# STM32G030 register map
File version: 1.6
CPU: CM0 r0p1, little endian, MPU, no FPU, 2 interrupt priority bits
Registers are 32-bit, read-write, reset 0x0 unless marked. A register's access mark holds for its fields unless they carry their own. Offsets are from the block's base; [hi:lo] are bit positions; {n}, {i} and the like mark numbered series.

## FLASH
Base 0x40022000
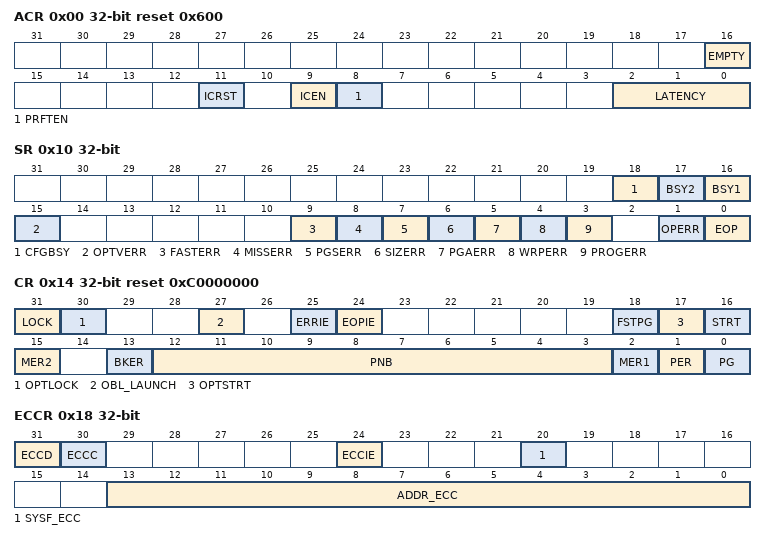
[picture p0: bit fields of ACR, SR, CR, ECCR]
0x00 ACR reset 0x600 — Access control register
  [16] EMPTY — Flash User area empty
  [11] ICRST — Instruction cache reset
  [9] ICEN — Instruction cache enable
  [8] PRFTEN — Prefetch enable
  [2:0] LATENCY
0x08 KEYR wo — Flash key register
  [31:0] KEY — KEYR
0x0C OPTKEYR wo — Option byte key register
  [31:0] OPTKEY — Option byte key
0x10 SR — Status register
  [18] CFGBSY — Programming or erase configuration busy.
  [17] BSY2
  [16] BSY1
  [15] OPTVERR — Option and Engineering bits loading validity error
  [9] FASTERR — Fast programming error
  [8] MISSERR — Fast programming data miss error
  [7] PGSERR — Programming sequence error
  [6] SIZERR — Size error
  [5] PGAERR — Programming alignment error
  [4] WRPERR — Write protected error
  [3] PROGERR — Programming error
  [1] OPERR — Operation error
  [0] EOP — End of operation
0x14 CR reset 0xC0000000 — Flash control register
  [31] LOCK — FLASH_CR Lock
  [30] OPTLOCK — Options Lock
  [27] OBL_LAUNCH — Force the option byte loading
  [25] ERRIE — Error interrupt enable
  [24] EOPIE — End of operation interrupt enable
  [18] FSTPG — Fast programming
  [17] OPTSTRT — Options modification start
  [16] STRT — Start
  [15] MER2
  [13] BKER
  [12:3] PNB — Page number
  [2] MER1 — Mass erase
  [1] PER — Page erase
  [0] PG — Programming
0x18 ECCR access per field — Flash ECC register
  [31] ECCD rw — ECC detection
  [30] ECCC rw — ECC correction
  [24] ECCIE rw — ECC correction interrupt enable
  [20] SYSF_ECC ro — ECC fail for Corrected ECC Error or Double ECC Error in info block
  [13:0] ADDR_ECC ro — ECC fail address
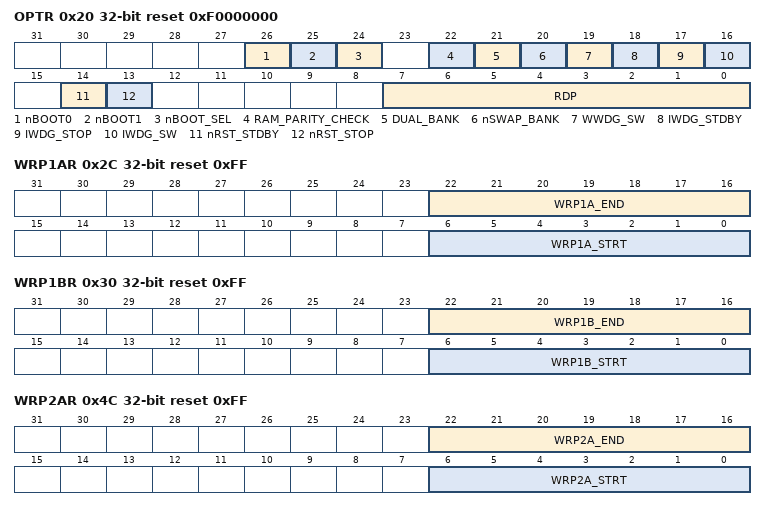
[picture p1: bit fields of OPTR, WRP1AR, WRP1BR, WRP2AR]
0x20 OPTR reset 0xF0000000 — Flash option register
  [26] nBOOT0 — nBOOT0 option bit
  [25] nBOOT1 — Boot configuration
  [24] nBOOT_SEL
  [22] RAM_PARITY_CHECK — SRAM parity check control
  [21] DUAL_BANK
  [20] nSWAP_BANK
  [19] WWDG_SW — Window watchdog selection
  [18] IWDG_STDBY — Independent watchdog counter freeze in Standby mode
  [17] IWDG_STOP — Independent watchdog counter freeze in Stop mode
  [16] IWDG_SW — Independent watchdog selection
  [14] nRST_STDBY
  [13] nRST_STOP
  [7:0] RDP — Read protection level
0x2C WRP1AR reset 0xFF — Flash WRP area A address register
  [22:16] WRP1A_END — WRP area A end offset
  [6:0] WRP1A_STRT — WRP area A start offset
0x30 WRP1BR reset 0xFF — Flash WRP area B address register
  [22:16] WRP1B_END — WRP area B end offset
  [6:0] WRP1B_STRT — WRP area B start offset
0x4C WRP2AR reset 0xFF — FLASH WRP2 area A address register
  [22:16] WRP2A_END, [6:0] WRP2A_STRT
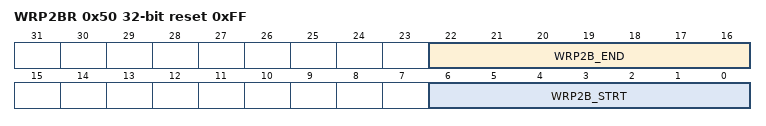
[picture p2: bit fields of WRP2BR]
0x50 WRP2BR reset 0xFF — FLASH WRP2 area B address register
  [22:16] WRP2B_END, [6:0] WRP2B_STRT

## PWR — Power control
Base 0x40007000
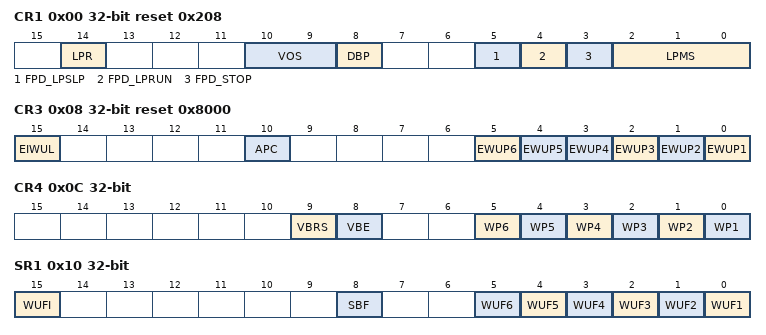
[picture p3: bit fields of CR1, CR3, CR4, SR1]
0x00 CR1 reset 0x208 — Power control register 1
  [14] LPR — Low-power run
  [10:9] VOS — Voltage scaling range selection
  [8] DBP — Disable backup domain write protection
  [5] FPD_LPSLP — Flash memory powered down during Low-power sleep mode
  [4] FPD_LPRUN — Flash memory powered down during Low-power run mode
  [3] FPD_STOP — Flash memory powered down during Stop mode
  [2:0] LPMS — Low-power mode selection
0x04 CR2 — Power control register 2
  [10] USV
0x08 CR3 reset 0x8000 — Power control register 3
  [15] EIWUL — Enable internal wakeup line
  [10] APC — Apply pull-up and pull-down configuration
  [5] EWUP6 — Enable WKUP6 wakeup pin
  [4] EWUP5 — Enable WKUP5 wakeup pin
  [n-1] EWUP{n} (n=1..4) — Enable Wakeup pin WKUP{n}
0x0C CR4 — Power control register 4
  [9] VBRS — VBAT battery charging resistor selection
  [8] VBE — VBAT battery charging enable
  [5] WP6 — WKUP6 wakeup pin polarity
  [n-1] WP{n} (n=1..5) — Wakeup pin WKUP{n} polarity
0x10 SR1 ro — Power status register 1
  [15] WUFI — Wakeup flag internal
  [8] SBF — Standby flag
  [n-1] WUF{n} (n=1..6) — Wakeup flag {n}
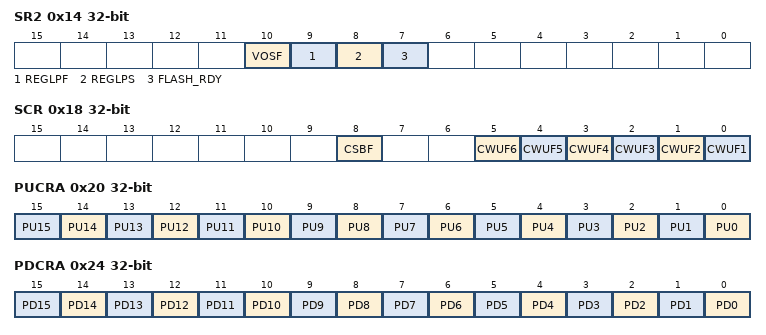
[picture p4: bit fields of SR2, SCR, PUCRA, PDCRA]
0x14 SR2 ro — Power status register 2
  [10] VOSF — Voltage scaling flag
  [9] REGLPF — Low-power regulator flag
  [8] REGLPS — Low-power regulator started
  [7] FLASH_RDY — Flash ready flag
0x18 SCR wo — Power status clear register
  [8] CSBF — Clear standby flag
  [n-1] CWUF{n} (n=1..6) — Clear wakeup flag {n}
0x20 PUCRA — Power Port A pull-up control register
  [n] PU{n} (n=0..15) — Port A pull-up bit y (y=0..15)
0x24 PDCRA — Power Port A pull-down control register
  [n] PD{n} (n=0..15) — Port A pull-down bit y (y=0..15)
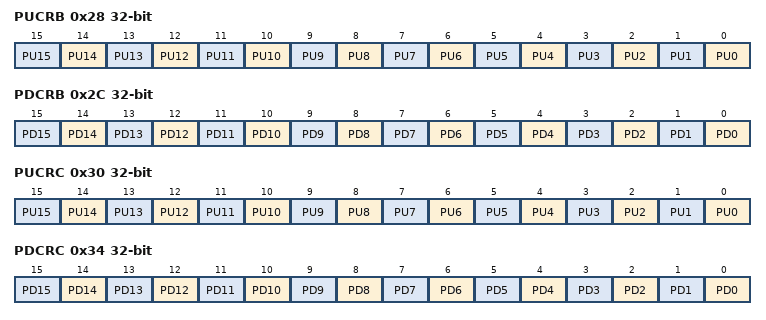
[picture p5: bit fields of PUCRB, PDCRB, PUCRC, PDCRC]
0x28 PUCRB — Power Port B pull-up control register
  [n] PU{n} (n=0..15) — Port B pull-up bit y (y=0..15)
0x2C PDCRB — Power Port B pull-down control register
  [n] PD{n} (n=0..15) — Port B pull-down bit y (y=0..15)
0x30 PUCRC — Power Port C pull-up control register
  [n] PU{n} (n=0..15) — Port C pull-up bit y (y=0..15)
0x34 PDCRC — Power Port C pull-down control register
  [n] PD{n} (n=0..15) — Port C pull-down bit y (y=0..15)
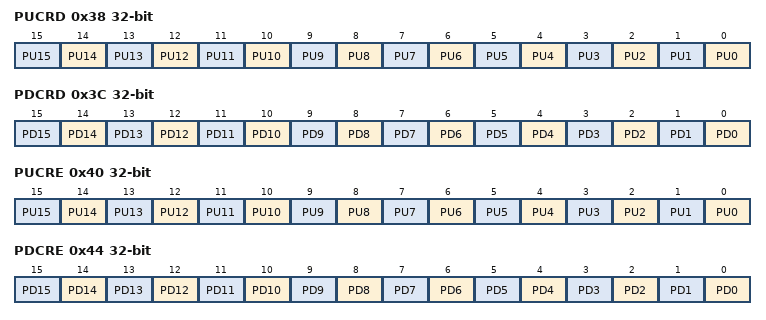
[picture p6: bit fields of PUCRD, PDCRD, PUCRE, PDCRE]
0x38 PUCRD — Power Port D pull-up control register
  [n] PU{n} (n=0..15) — Port D pull-up bit y (y=0..15)
0x3C PDCRD — Power Port D pull-down control register
  [n] PD{n} (n=0..15) — Port D pull-down bit y (y=0..15)
0x40 PUCRE — Power Port E pull-UP control register
  [n] PU{n} (n=0..15) — Port E pull-up bit y (y=0..15)
0x44 PDCRE — Power Port E pull-down control register
  [n] PD{n} (n=0..15) — Port E pull-down bit y (y=0..15)
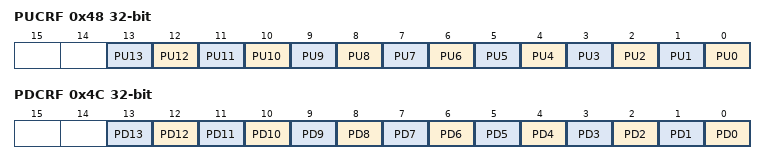
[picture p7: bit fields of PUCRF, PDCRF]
0x48 PUCRF — Power Port F pull-up control register
  [n] PU{n} (n=0..13) — Port F pull-up bit y (y=0..15)
0x4C PDCRF — Power Port F pull-down control register
  [n] PD{n} (n=0..13) — Port F pull-down bit y (y=0..15)
